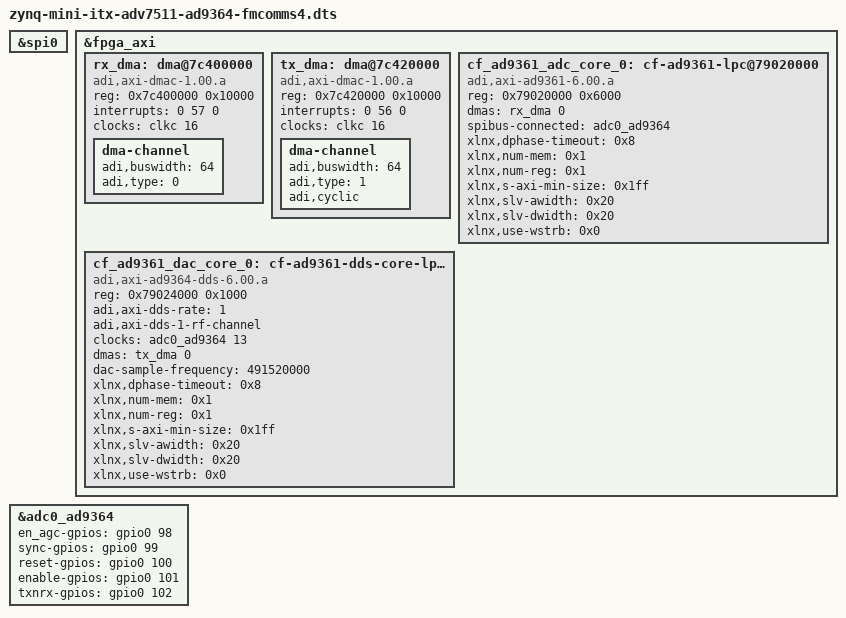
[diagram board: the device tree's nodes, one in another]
/dts-v1/;

/include/ "zynq-mini-itx.dtsi"
/include/ "zynq-mini-itx-adv7511.dtsi"

&spi0 {
	status = "okay";
};

#define fmc_spi spi0

&fpga_axi  {
	rx_dma: dma@7c400000 {
		compatible = "adi,axi-dmac-1.00.a";
		reg = <0x7c400000 0x10000>;
		#dma-cells = <1>;
		interrupts = <0 57 0>;
		clocks = <&clkc 16>;

		dma-channel {
			adi,buswidth = <64>;
			adi,type = <0>;
		};
	};

	tx_dma: dma@7c420000 {
		compatible = "adi,axi-dmac-1.00.a";
		reg = <0x7c420000 0x10000>;
		#dma-cells = <1>;
		interrupts = <0 56 0>;
		clocks = <&clkc 16>;

		dma-channel {
			adi,buswidth = <64>;
			adi,type = <1>;
			adi,cyclic;
		};
	};

	cf_ad9361_adc_core_0: cf-ad9361-lpc@79020000 {
		compatible = "adi,axi-ad9361-6.00.a";
		reg = <0x79020000 0x6000>;
		dmas = <&rx_dma 0>;
		dma-names = "rx";
		spibus-connected = <&adc0_ad9364>;
		xlnx,dphase-timeout = <0x8>;
		xlnx,num-mem = <0x1>;
		xlnx,num-reg = <0x1>;
		xlnx,s-axi-min-size = <0x1ff>;
		xlnx,slv-awidth = <0x20>;
		xlnx,slv-dwidth = <0x20>;
		xlnx,use-wstrb = <0x0>;
	};

	cf_ad9361_dac_core_0: cf-ad9361-dds-core-lpc@79024000 {
		compatible = "adi,axi-ad9364-dds-6.00.a";
		reg = <0x79024000 0x1000>;

		adi,axi-dds-rate = <1>; /* use 1 for 1RX1TX mode */
		adi,axi-dds-1-rf-channel;

		clocks = <&adc0_ad9364 13>;
		clock-names = "sampl_clk";
		dmas = <&tx_dma 0>;
		dma-names = "tx";
		dac-sample-frequency = <491520000>;
		xlnx,dphase-timeout = <0x8>;
		xlnx,num-mem = <0x1>;
		xlnx,num-reg = <0x1>;
		xlnx,s-axi-min-size = <0x1ff>;
		xlnx,slv-awidth = <0x20>;
		xlnx,slv-dwidth = <0x20>;
		xlnx,use-wstrb = <0x0>;
	};
};

#include "adi-fmcomms4.dtsi"

&adc0_ad9364 {
	en_agc-gpios = <&gpio0 98 0>;
	sync-gpios = <&gpio0 99 0>;
	reset-gpios = <&gpio0 100 0>;
	enable-gpios = <&gpio0 101 0>;
	txnrx-gpios = <&gpio0 102 0>;
};
